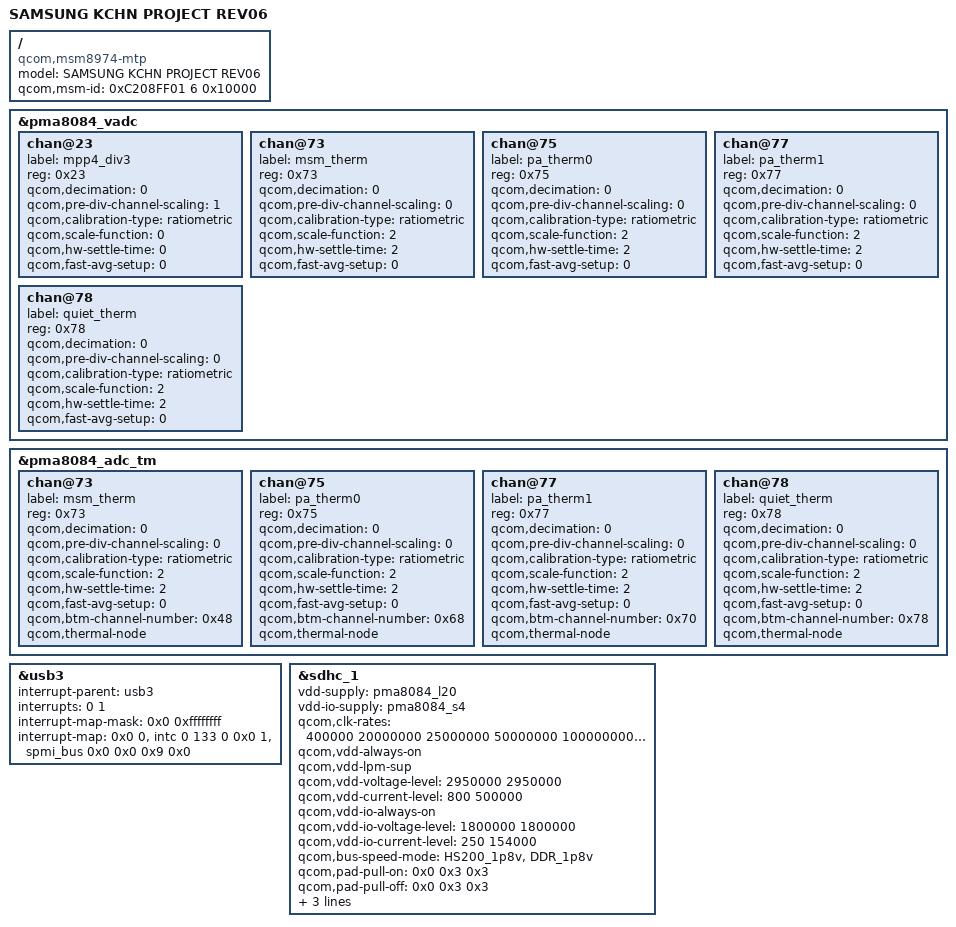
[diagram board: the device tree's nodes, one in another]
/* Copyright (c) 2013, The Linux Foundation. All rights reserved.
 *
 * This program is free software; you can redistribute it and/or modify
 * it under the terms of the GNU General Public License version 2 and
 * only version 2 as published by the Free Software Foundation.
 *
 * This program is distributed in the hope that it will be useful,
 * but WITHOUT ANY WARRANTY; without even the implied warranty of
 * MERCHANTABILITY or FITNESS FOR A PARTICULAR PURPOSE.  See the
 * GNU General Public License for more details.
 */

/dts-v1/;

/include/ "msm8974pro-sec.dtsi"
/include/ "msm8974pro-max77804k-k.dtsi"
/include/ "msm8974pro-ac-sec-k-r06.dtsi"

/ {
	model = "SAMSUNG KCHN PROJECT REV06";
	compatible = "qcom,msm8974-mtp", "qcom,msm8974", "qcom,mtp";
	/*QCOM BOARD REV TYPE...*/
	/*qcom,msm-id = <194 8 0x10000>;*/
	/*SEC BOARD REV TYPE...*/
        qcom,msm-id = <0xC208FF01 6 0x10000>;
        /* [31:24] chip-id, [23:16] platform-id, [15:8] national code, [7:0] operator revision, reserved */
};

&pma8084_vadc {
	chan@23 {
		label = "mpp4_div3";
		reg = <0x23>;
		qcom,decimation = <0>;
		qcom,pre-div-channel-scaling = <1>; /* 1:3 scaling */
		qcom,calibration-type = "ratiometric";
		qcom,scale-function = <0>;
		qcom,hw-settle-time = <0>;
		qcom,fast-avg-setup = <0>;
	};

	chan@73 {
		label = "msm_therm";
		reg = <0x73>;
		qcom,decimation = <0>;
		qcom,pre-div-channel-scaling = <0>;
		qcom,calibration-type = "ratiometric";
		qcom,scale-function = <2>;
		qcom,hw-settle-time = <2>;
		qcom,fast-avg-setup = <0>;
	};

	chan@75 {
		label = "pa_therm0";
		reg = <0x75>;
		qcom,decimation = <0>;
		qcom,pre-div-channel-scaling = <0>;
		qcom,calibration-type = "ratiometric";
		qcom,scale-function = <2>;
		qcom,hw-settle-time = <2>;
		qcom,fast-avg-setup = <0>;
	};

	chan@77 {
		label = "pa_therm1";
		reg = <0x77>;
		qcom,decimation = <0>;
		qcom,pre-div-channel-scaling = <0>;
		qcom,calibration-type = "ratiometric";
		qcom,scale-function = <2>;
		qcom,hw-settle-time = <2>;
		qcom,fast-avg-setup = <0>;
	};

	chan@78 {
		label = "quiet_therm";
		reg = <0x78>;
		qcom,decimation = <0>;
		qcom,pre-div-channel-scaling = <0>;
		qcom,calibration-type = "ratiometric";
		qcom,scale-function = <2>;
		qcom,hw-settle-time = <2>;
		qcom,fast-avg-setup = <0>;
	};
};

&pma8084_adc_tm {
	chan@73 {
		label = "msm_therm";
		reg = <0x73>;
		qcom,decimation = <0>;
		qcom,pre-div-channel-scaling = <0>;
		qcom,calibration-type = "ratiometric";
		qcom,scale-function = <2>;
		qcom,hw-settle-time = <2>;
		qcom,fast-avg-setup = <0>;
		qcom,btm-channel-number = <0x48>;
		qcom,thermal-node;
	};

	chan@75 {
		label = "pa_therm0";
		reg = <0x75>;
		qcom,decimation = <0>;
		qcom,pre-div-channel-scaling = <0>;
		qcom,calibration-type = "ratiometric";
		qcom,scale-function = <2>;
		qcom,hw-settle-time = <2>;
		qcom,fast-avg-setup = <0>;
		qcom,btm-channel-number = <0x68>;
		qcom,thermal-node;
	};

	chan@77 {
		label = "pa_therm1";
		reg = <0x77>;
		qcom,decimation = <0>;
		qcom,pre-div-channel-scaling = <0>;
		qcom,calibration-type = "ratiometric";
		qcom,scale-function = <2>;
		qcom,hw-settle-time = <2>;
		qcom,fast-avg-setup = <0>;
		qcom,btm-channel-number = <0x70>;
		qcom,thermal-node;
	};

	chan@78 {
		label = "quiet_therm";
		reg = <0x78>;
		qcom,decimation = <0>;
		qcom,pre-div-channel-scaling = <0>;
		qcom,calibration-type = "ratiometric";
		qcom,scale-function = <2>;
		qcom,hw-settle-time = <2>;
		qcom,fast-avg-setup = <0>;
		qcom,btm-channel-number = <0x78>;
		qcom,thermal-node;
	};
};

&usb3 {
	interrupt-names = "irq", "otg_irq", "hs_phy_irq", "pmic_id_irq";
	interrupt-parent = <&usb3>;
	interrupts = <0 1>;
	#interrupt-cells = <1>;
	interrupt-map-mask = <0x0 0xffffffff>;
	interrupt-map = <0x0 0 &intc 0 133 0
			 0x0 1 &spmi_bus 0x0 0x0 0x9 0x0>;
	interrupt-names = "hs_phy_irq", "pmic_id_irq";
	/*qcom,misc-ref = <&pm8941_misc>;*/
};

&sdhc_1 {
	vdd-supply = <&pma8084_l20>;
	vdd-io-supply = <&pma8084_s4>;

	qcom,clk-rates = <400000 20000000 25000000 50000000 100000000 192000000>;

	qcom,vdd-always-on;
	qcom,vdd-lpm-sup;
	qcom,vdd-voltage-level = <2950000 2950000>;
	qcom,vdd-current-level = <800 500000>;

	qcom,vdd-io-always-on;
	qcom,vdd-io-voltage-level = <1800000 1800000>;
	qcom,vdd-io-current-level = <250 154000>;

	qcom,bus-speed-mode = "HS200_1p8v", "DDR_1p8v";

	qcom,pad-pull-on = <0x0 0x3 0x3>; /* no-pull, pull-up, pull-up */
	qcom,pad-pull-off = <0x0 0x3 0x3>; /* no-pull, pull-up, pull-up */
	qcom,pad-drv-on = <0x7 0x4 0x4>; /* 16mA, 10mA, 10mA */
	qcom,pad-drv-off = <0x0 0x0 0x0>; /* 2mA, 2mA, 2mA */

	qcom,nonremovable;
	status = "ok";
};
